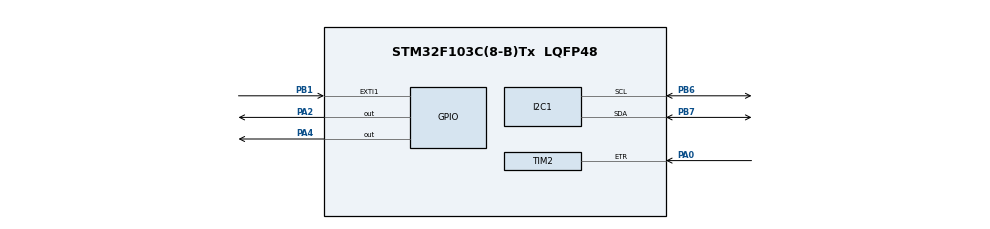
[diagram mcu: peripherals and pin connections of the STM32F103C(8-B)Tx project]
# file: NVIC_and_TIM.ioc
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Mcu.Family=STM32F1
Mcu.Name=STM32F103C(8-B)Tx
Mcu.Package=LQFP48
NVIC.EXTI1_IRQn=true\:15\:0\:true\:false\:true\:true\:true\:true
NVIC.PriorityGroup=NVIC_PRIORITYGROUP_4
NVIC.TIM2_IRQn=true\:0\:0\:false\:false\:true\:true\:true\:true
PA0-WKUP.Signal=S_TIM2_CH1_ETR
PA13.Mode=Serial_Wire
PA13.Signal=SYS_JTMS-SWDIO
PA14.Mode=Serial_Wire
PA14.Signal=SYS_JTCK-SWCLK
PA2.GPIO_PuPd=GPIO_PULLUP
PA2.PinState=GPIO_PIN_SET
PA2.Signal=GPIO_Output
PA4.GPIO_PuPd=GPIO_PULLDOWN
PA4.PinState=GPIO_PIN_SET
PA4.Signal=GPIO_Output
PB1.GPIO_ModeDefaultEXTI=GPIO_MODE_IT_FALLING
PB1.GPIO_PuPd=GPIO_PULLUP
PB1.Signal=GPXTI1
PB6.Mode=I2C
PB6.Signal=I2C1_SCL
PB7.Mode=I2C
PB7.Signal=I2C1_SDA
ProjectManager.HeapSize=0x200
ProjectManager.StackSize=0x400
ProjectManager.TargetToolchain=STM32CubeIDE
RCC.APB1Freq_Value=8000000
RCC.APB2Freq_Value=8000000
SH.S_TIM2_CH1_ETR.0=TIM2_ETR,ClockSourceETR_Mode2
TIM2.ClockFilter=15
board=custom

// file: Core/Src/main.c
/* USER CODE BEGIN Header */
/**
  ******************************************************************************
  * @file           : main.c
  * @brief          : Main program body
  ******************************************************************************
  * @attention
  *
  * Copyright (c) 2025 STMicroelectronics.
  * All rights reserved.
  *
  * This software is licensed under terms that can be found in the LICENSE file
  * in the root directory of this software component.
  * If no LICENSE file comes with this software, it is provided AS-IS.
  *
  ******************************************************************************
  */
/* USER CODE END Header */
#include "main.h"
#include "i2c.h"
#include "tim.h"
#include "gpio.h"

/* USER CODE BEGIN Includes */
#include "oled.h"
#include<string.h>
#include<stdio.h>
/* USER CODE END Includes */

/* USER CODE BEGIN PV */
int cnt = 0;
char message[20] = "";
int mode = 0;
/* USER CODE END PV */

void SystemClock_Config(void);

int main(void)
{

  /* MCU Configuration--------------------------------------------------------*/

  /* Reset of all peripherals, Initializes the Flash interface and the Systick. */
  HAL_Init();

  /* Configure the system clock */
  SystemClock_Config();

  /* Initialize all configured peripherals */
  MX_GPIO_Init();
  MX_I2C1_Init();
  MX_TIM2_Init();
  /* USER CODE BEGIN 2 */
  OLED_Init();
  /* USER CODE END 2 */

  /* Infinite loop */
  /* USER CODE BEGIN WHILE */
  while (1)
  {
	  OLED_NewFrame();

	  sprintf(message,"IT times: %d",cnt);
	  OLED_PrintString(0, 0, message, &font16x16, OLED_COLOR_NORMAL);

	  OLED_ShowFrame();
	  HAL_GPIO_WritePin(GPIOA, GPIO_PIN_4, GPIO_PIN_RESET);
    /* USER CODE END WHILE */

  }
}

void SystemClock_Config(void)
{
  RCC_OscInitTypeDef RCC_OscInitStruct = {0};
  RCC_ClkInitTypeDef RCC_ClkInitStruct = {0};

  /** Initializes the RCC Oscillators according to the specified parameters
  * in the RCC_OscInitTypeDef structure.
  */
  RCC_OscInitStruct.OscillatorType = RCC_OSCILLATORTYPE_HSI;
  RCC_OscInitStruct.HSIState = RCC_HSI_ON;
  RCC_OscInitStruct.HSICalibrationValue = RCC_HSICALIBRATION_DEFAULT;
  RCC_OscInitStruct.PLL.PLLState = RCC_PLL_NONE;
  if (HAL_RCC_OscConfig(&RCC_OscInitStruct) != HAL_OK)
  {
    Error_Handler();
  }

  /** Initializes the CPU, AHB and APB buses clocks
  */
  RCC_ClkInitStruct.ClockType = RCC_CLOCKTYPE_HCLK|RCC_CLOCKTYPE_SYSCLK
                              |RCC_CLOCKTYPE_PCLK1|RCC_CLOCKTYPE_PCLK2;
  RCC_ClkInitStruct.SYSCLKSource = RCC_SYSCLKSOURCE_HSI;
  RCC_ClkInitStruct.AHBCLKDivider = RCC_SYSCLK_DIV1;
  RCC_ClkInitStruct.APB1CLKDivider = RCC_HCLK_DIV1;
  RCC_ClkInitStruct.APB2CLKDivider = RCC_HCLK_DIV1;

  if (HAL_RCC_ClockConfig(&RCC_ClkInitStruct, FLASH_LATENCY_0) != HAL_OK)
  {
    Error_Handler();
  }
}

void Error_Handler(void)
{
  __disable_irq();
  while (1)
  {
  }
}
